AUTOSAR XML (schema 4-0-3)
standard types defined: Boolean, UInt16
package /AUTOSAR_Platform/DataConstrs
  range DC_Boolean: raw 0..1
  range DC_UInt16: raw 0..65535
package /PATAC/MSM/ComponentTypes
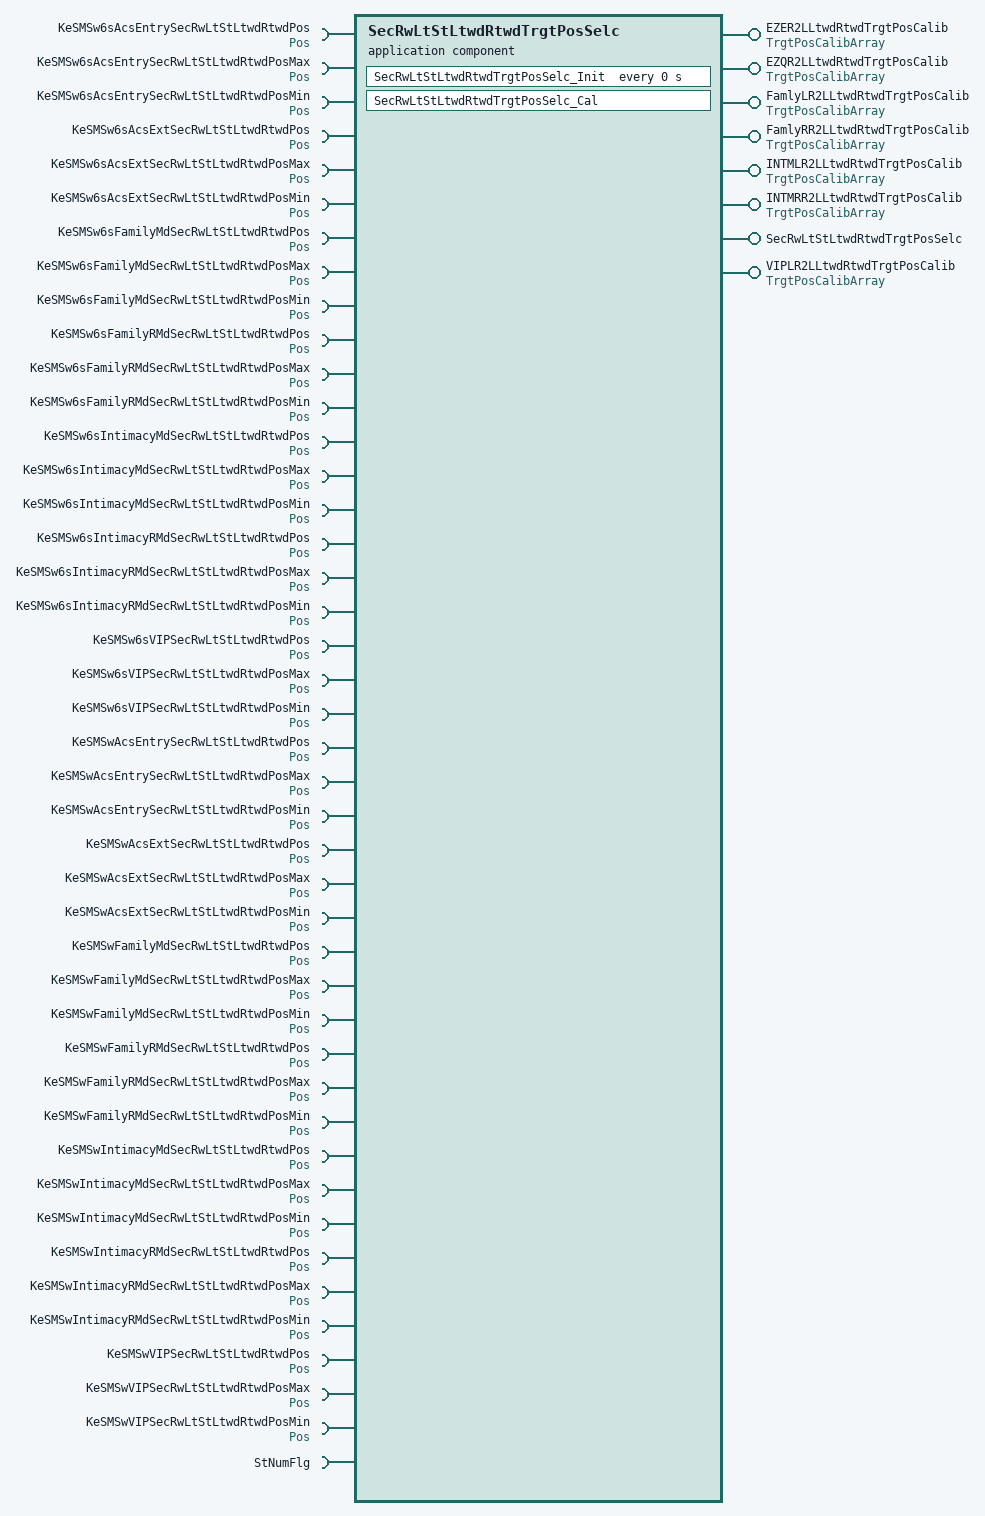
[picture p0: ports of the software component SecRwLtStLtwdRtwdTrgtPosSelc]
  application sw component type SecRwLtStLtwdRtwdTrgtPosSelc
    8 x provide port:
      EZER2LLtwdRtwdTrgtPosCalib: nonqueued-sender-com-spec{data-element=TrgtPosArray, init-value=[4095, 4095, 4095]}, provided-interface=TrgtPosCalibArray
      EZQR2LLtwdRtwdTrgtPosCalib: nonqueued-sender-com-spec{data-element=TrgtPosArray, init-value=[4095, 4095, 4095]}, provided-interface=TrgtPosCalibArray
      FamlyLR2LLtwdRtwdTrgtPosCalib: nonqueued-sender-com-spec{data-element=TrgtPosArray, init-value=[4095, 4095, 4095]}, provided-interface=TrgtPosCalibArray
      FamlyRR2LLtwdRtwdTrgtPosCalib: nonqueued-sender-com-spec{data-element=TrgtPosArray, init-value=[4095, 4095, 4095]}, provided-interface=TrgtPosCalibArray
      INTMLR2LLtwdRtwdTrgtPosCalib: nonqueued-sender-com-spec{data-element=TrgtPosArray, init-value=[4095, 4095, 4095]}, provided-interface=TrgtPosCalibArray
      INTMRR2LLtwdRtwdTrgtPosCalib: nonqueued-sender-com-spec{data-element=TrgtPosArray, init-value=[4095, 4095, 4095]}, provided-interface=TrgtPosCalibArray
      SecRwLtStLtwdRtwdTrgtPosSelc: server-com-spec{operation=Cal, queue-length=1}, provided-interface=SecRwLtStLtwdRtwdTrgtPosSelc
      VIPLR2LLtwdRtwdTrgtPosCalib: nonqueued-sender-com-spec{data-element=TrgtPosArray, init-value=[4095, 4095, 4095]}, provided-interface=TrgtPosCalibArray
    43 x require port:
      KeSMSw6sAcsEntrySecRwLtStLtwdRtwdPos: parameter-require-com-spec{init-value=0, parameter=Val}, required-interface=Pos
      KeSMSw6sAcsEntrySecRwLtStLtwdRtwdPosMax: parameter-require-com-spec{init-value=0, parameter=Val}, required-interface=Pos
      KeSMSw6sAcsEntrySecRwLtStLtwdRtwdPosMin: parameter-require-com-spec{init-value=0, parameter=Val}, required-interface=Pos
      KeSMSw6sAcsExtSecRwLtStLtwdRtwdPos: parameter-require-com-spec{init-value=0, parameter=Val}, required-interface=Pos
      KeSMSw6sAcsExtSecRwLtStLtwdRtwdPosMax: parameter-require-com-spec{init-value=0, parameter=Val}, required-interface=Pos
      KeSMSw6sAcsExtSecRwLtStLtwdRtwdPosMin: parameter-require-com-spec{init-value=0, parameter=Val}, required-interface=Pos
      KeSMSw6sFamilyMdSecRwLtStLtwdRtwdPos: parameter-require-com-spec{init-value=0, parameter=Val}, required-interface=Pos
      KeSMSw6sFamilyMdSecRwLtStLtwdRtwdPosMax: parameter-require-com-spec{init-value=0, parameter=Val}, required-interface=Pos
      KeSMSw6sFamilyMdSecRwLtStLtwdRtwdPosMin: parameter-require-com-spec{init-value=0, parameter=Val}, required-interface=Pos
      KeSMSw6sFamilyRMdSecRwLtStLtwdRtwdPos: parameter-require-com-spec{init-value=0, parameter=Val}, required-interface=Pos
      KeSMSw6sFamilyRMdSecRwLtStLtwdRtwdPosMax: parameter-require-com-spec{init-value=0, parameter=Val}, required-interface=Pos
      KeSMSw6sFamilyRMdSecRwLtStLtwdRtwdPosMin: parameter-require-com-spec{init-value=0, parameter=Val}, required-interface=Pos
      KeSMSw6sIntimacyMdSecRwLtStLtwdRtwdPos: parameter-require-com-spec{init-value=0, parameter=Val}, required-interface=Pos
      KeSMSw6sIntimacyMdSecRwLtStLtwdRtwdPosMax: parameter-require-com-spec{init-value=0, parameter=Val}, required-interface=Pos
      KeSMSw6sIntimacyMdSecRwLtStLtwdRtwdPosMin: parameter-require-com-spec{init-value=0, parameter=Val}, required-interface=Pos
      KeSMSw6sIntimacyRMdSecRwLtStLtwdRtwdPos: parameter-require-com-spec{init-value=0, parameter=Val}, required-interface=Pos
      KeSMSw6sIntimacyRMdSecRwLtStLtwdRtwdPosMax: parameter-require-com-spec{init-value=0, parameter=Val}, required-interface=Pos
      KeSMSw6sIntimacyRMdSecRwLtStLtwdRtwdPosMin: parameter-require-com-spec{init-value=0, parameter=Val}, required-interface=Pos
      KeSMSw6sVIPSecRwLtStLtwdRtwdPos: parameter-require-com-spec{init-value=4000, parameter=Val}, required-interface=Pos
      KeSMSw6sVIPSecRwLtStLtwdRtwdPosMax: parameter-require-com-spec{init-value=4000, parameter=Val}, required-interface=Pos
      KeSMSw6sVIPSecRwLtStLtwdRtwdPosMin: parameter-require-com-spec{init-value=4000, parameter=Val}, required-interface=Pos
      KeSMSwAcsEntrySecRwLtStLtwdRtwdPos: parameter-require-com-spec{init-value=0, parameter=Val}, required-interface=Pos
      KeSMSwAcsEntrySecRwLtStLtwdRtwdPosMax: parameter-require-com-spec{init-value=0, parameter=Val}, required-interface=Pos
      KeSMSwAcsEntrySecRwLtStLtwdRtwdPosMin: parameter-require-com-spec{init-value=0, parameter=Val}, required-interface=Pos
      KeSMSwAcsExtSecRwLtStLtwdRtwdPos: parameter-require-com-spec{init-value=0, parameter=Val}, required-interface=Pos
      KeSMSwAcsExtSecRwLtStLtwdRtwdPosMax: parameter-require-com-spec{init-value=0, parameter=Val}, required-interface=Pos
      KeSMSwAcsExtSecRwLtStLtwdRtwdPosMin: parameter-require-com-spec{init-value=0, parameter=Val}, required-interface=Pos
      KeSMSwFamilyMdSecRwLtStLtwdRtwdPos: parameter-require-com-spec{init-value=0, parameter=Val}, required-interface=Pos
      KeSMSwFamilyMdSecRwLtStLtwdRtwdPosMax: parameter-require-com-spec{init-value=0, parameter=Val}, required-interface=Pos
      KeSMSwFamilyMdSecRwLtStLtwdRtwdPosMin: parameter-require-com-spec{init-value=0, parameter=Val}, required-interface=Pos
      KeSMSwFamilyRMdSecRwLtStLtwdRtwdPos: parameter-require-com-spec{init-value=0, parameter=Val}, required-interface=Pos
      KeSMSwFamilyRMdSecRwLtStLtwdRtwdPosMax: parameter-require-com-spec{init-value=0, parameter=Val}, required-interface=Pos
      KeSMSwFamilyRMdSecRwLtStLtwdRtwdPosMin: parameter-require-com-spec{init-value=0, parameter=Val}, required-interface=Pos
      KeSMSwIntimacyMdSecRwLtStLtwdRtwdPos: parameter-require-com-spec{init-value=0, parameter=Val}, required-interface=Pos
      KeSMSwIntimacyMdSecRwLtStLtwdRtwdPosMax: parameter-require-com-spec{init-value=0, parameter=Val}, required-interface=Pos
      KeSMSwIntimacyMdSecRwLtStLtwdRtwdPosMin: parameter-require-com-spec{init-value=0, parameter=Val}, required-interface=Pos
      KeSMSwIntimacyRMdSecRwLtStLtwdRtwdPos: parameter-require-com-spec{init-value=0, parameter=Val}, required-interface=Pos
      KeSMSwIntimacyRMdSecRwLtStLtwdRtwdPosMax: parameter-require-com-spec{init-value=0, parameter=Val}, required-interface=Pos
      KeSMSwIntimacyRMdSecRwLtStLtwdRtwdPosMin: parameter-require-com-spec{init-value=0, parameter=Val}, required-interface=Pos
      KeSMSwVIPSecRwLtStLtwdRtwdPos: parameter-require-com-spec{init-value=4000, parameter=Val}, required-interface=Pos
      KeSMSwVIPSecRwLtStLtwdRtwdPosMax: parameter-require-com-spec{init-value=4000, parameter=Val}, required-interface=Pos
      KeSMSwVIPSecRwLtStLtwdRtwdPosMin: parameter-require-com-spec{init-value=4000, parameter=Val}, required-interface=Pos
      StNumFlg: required-interface=StNumFlg
        required-com-specs:
          data-element=Is4s, filter=data-filter-type=ALWAYS, init-value=0
          data-element=Is6s, filter=data-filter-type=ALWAYS, init-value=0
          data-element=Is6s7s, filter=data-filter-type=ALWAYS, init-value=0
          data-element=Is7s, filter=data-filter-type=ALWAYS, init-value=0
    behavior SecRwLtStLtwdRtwdTrgtPosSelc_InternalBehavior
      operation invoked event OIT_SecRwLtStLtwdRtwdTrgtPosSelc_Cal_SecRwLtStLtwdRtwdTrgtPosSelc_Cal: start-on-event=SecRwLtStLtwdRtwdTrgtPosSelc_Cal, operation=SecRwLtStLtwdRtwdTrgtPosSelc.Cal
      timing event SecRwLtStLtwdRtwdTrgtPosSelc_InitEvent: start-on-event=SecRwLtStLtwdRtwdTrgtPosSelc_Init, period=0
      runnable SecRwLtStLtwdRtwdTrgtPosSelc_Cal
        data-receive-point-by-arguments:
          4 x access:
            REC_StNumFlg_Is4s: accessed-variable=StNumFlg.Is4s
            REC_StNumFlg_Is6s: accessed-variable=StNumFlg.Is6s
            REC_StNumFlg_Is6s7s: accessed-variable=StNumFlg.Is6s7s
            REC_StNumFlg_Is7s: accessed-variable=StNumFlg.Is7s
        data-send-points:
          7 x access:
            SEND_EZER2LLtwdRtwdTrgtPosCalib_TrgtPosArray: accessed-variable=EZER2LLtwdRtwdTrgtPosCalib.TrgtPosArray
            SEND_EZQR2LLtwdRtwdTrgtPosCalib_TrgtPosArray: accessed-variable=EZQR2LLtwdRtwdTrgtPosCalib.TrgtPosArray
            SEND_FamlyLR2LLtwdRtwdTrgtPosCalib_TrgtPosArray: accessed-variable=FamlyLR2LLtwdRtwdTrgtPosCalib.TrgtPosArray
            SEND_FamlyRR2LLtwdRtwdTrgtPosCalib_TrgtPosArray: accessed-variable=FamlyRR2LLtwdRtwdTrgtPosCalib.TrgtPosArray
            SEND_INTMLR2LLtwdRtwdTrgtPosCalib_TrgtPosArray: accessed-variable=INTMLR2LLtwdRtwdTrgtPosCalib.TrgtPosArray
            SEND_INTMRR2LLtwdRtwdTrgtPosCalib_TrgtPosArray: accessed-variable=INTMRR2LLtwdRtwdTrgtPosCalib.TrgtPosArray
            SEND_VIPLR2LLtwdRtwdTrgtPosCalib_TrgtPosArray: accessed-variable=VIPLR2LLtwdRtwdTrgtPosCalib.TrgtPosArray
        42 x parameter access:
          PA_KeSMSw6sAcsEntrySecRwLtStLtwdRtwdPos_Val: accessed-parameter=KeSMSw6sAcsEntrySecRwLtStLtwdRtwdPos.Val
          PA_KeSMSw6sAcsEntrySecRwLtStLtwdRtwdPosMax_Val: accessed-parameter=KeSMSw6sAcsEntrySecRwLtStLtwdRtwdPosMax.Val
          PA_KeSMSw6sAcsEntrySecRwLtStLtwdRtwdPosMin_Val: accessed-parameter=KeSMSw6sAcsEntrySecRwLtStLtwdRtwdPosMin.Val
          PA_KeSMSw6sAcsExtSecRwLtStLtwdRtwdPos_Val: accessed-parameter=KeSMSw6sAcsExtSecRwLtStLtwdRtwdPos.Val
          PA_KeSMSw6sAcsExtSecRwLtStLtwdRtwdPosMax_Val: accessed-parameter=KeSMSw6sAcsExtSecRwLtStLtwdRtwdPosMax.Val
          PA_KeSMSw6sAcsExtSecRwLtStLtwdRtwdPosMin_Val: accessed-parameter=KeSMSw6sAcsExtSecRwLtStLtwdRtwdPosMin.Val
          PA_KeSMSw6sFamilyMdSecRwLtStLtwdRtwdPos_Val: accessed-parameter=KeSMSw6sFamilyMdSecRwLtStLtwdRtwdPos.Val
          PA_KeSMSw6sFamilyMdSecRwLtStLtwdRtwdPosMax_Val: accessed-parameter=KeSMSw6sFamilyMdSecRwLtStLtwdRtwdPosMax.Val
          PA_KeSMSw6sFamilyMdSecRwLtStLtwdRtwdPosMin_Val: accessed-parameter=KeSMSw6sFamilyMdSecRwLtStLtwdRtwdPosMin.Val
          PA_KeSMSw6sFamilyRMdSecRwLtStLtwdRtwdPos_Val: accessed-parameter=KeSMSw6sFamilyRMdSecRwLtStLtwdRtwdPos.Val
          PA_KeSMSw6sFamilyRMdSecRwLtStLtwdRtwdPosMax_Val: accessed-parameter=KeSMSw6sFamilyRMdSecRwLtStLtwdRtwdPosMax.Val
          PA_KeSMSw6sFamilyRMdSecRwLtStLtwdRtwdPosMin_Val: accessed-parameter=KeSMSw6sFamilyRMdSecRwLtStLtwdRtwdPosMin.Val
          PA_KeSMSw6sIntimacyMdSecRwLtStLtwdRtwdPos_Val: accessed-parameter=KeSMSw6sIntimacyMdSecRwLtStLtwdRtwdPos.Val
          PA_KeSMSw6sIntimacyMdSecRwLtStLtwdRtwdPosMax_Val: accessed-parameter=KeSMSw6sIntimacyMdSecRwLtStLtwdRtwdPosMax.Val
          PA_KeSMSw6sIntimacyMdSecRwLtStLtwdRtwdPosMin_Val: accessed-parameter=KeSMSw6sIntimacyMdSecRwLtStLtwdRtwdPosMin.Val
          PA_KeSMSw6sIntimacyRMdSecRwLtStLtwdRtwdPos_Val: accessed-parameter=KeSMSw6sIntimacyRMdSecRwLtStLtwdRtwdPos.Val
          PA_KeSMSw6sIntimacyRMdSecRwLtStLtwdRtwdPosMax_Val: accessed-parameter=KeSMSw6sIntimacyRMdSecRwLtStLtwdRtwdPosMax.Val
          PA_KeSMSw6sIntimacyRMdSecRwLtStLtwdRtwdPosMin_Val: accessed-parameter=KeSMSw6sIntimacyRMdSecRwLtStLtwdRtwdPosMin.Val
          PA_KeSMSw6sVIPSecRwLtStLtwdRtwdPos_Val: accessed-parameter=KeSMSw6sVIPSecRwLtStLtwdRtwdPos.Val
          PA_KeSMSw6sVIPSecRwLtStLtwdRtwdPosMax_Val: accessed-parameter=KeSMSw6sVIPSecRwLtStLtwdRtwdPosMax.Val
          PA_KeSMSw6sVIPSecRwLtStLtwdRtwdPosMin_Val: accessed-parameter=KeSMSw6sVIPSecRwLtStLtwdRtwdPosMin.Val
          PA_KeSMSwAcsEntrySecRwLtStLtwdRtwdPos_Val: accessed-parameter=KeSMSwAcsEntrySecRwLtStLtwdRtwdPos.Val
          PA_KeSMSwAcsEntrySecRwLtStLtwdRtwdPosMax_Val: accessed-parameter=KeSMSwAcsEntrySecRwLtStLtwdRtwdPosMax.Val
          PA_KeSMSwAcsEntrySecRwLtStLtwdRtwdPosMin_Val: accessed-parameter=KeSMSwAcsEntrySecRwLtStLtwdRtwdPosMin.Val
          PA_KeSMSwAcsExtSecRwLtStLtwdRtwdPos_Val: accessed-parameter=KeSMSwAcsExtSecRwLtStLtwdRtwdPos.Val
          PA_KeSMSwAcsExtSecRwLtStLtwdRtwdPosMax_Val: accessed-parameter=KeSMSwAcsExtSecRwLtStLtwdRtwdPosMax.Val
          PA_KeSMSwAcsExtSecRwLtStLtwdRtwdPosMin_Val: accessed-parameter=KeSMSwAcsExtSecRwLtStLtwdRtwdPosMin.Val
          PA_KeSMSwFamilyMdSecRwLtStLtwdRtwdPos_Val: accessed-parameter=KeSMSwFamilyMdSecRwLtStLtwdRtwdPos.Val
          PA_KeSMSwFamilyMdSecRwLtStLtwdRtwdPosMax_Val: accessed-parameter=KeSMSwFamilyMdSecRwLtStLtwdRtwdPosMax.Val
          PA_KeSMSwFamilyMdSecRwLtStLtwdRtwdPosMin_Val: accessed-parameter=KeSMSwFamilyMdSecRwLtStLtwdRtwdPosMin.Val
          PA_KeSMSwFamilyRMdSecRwLtStLtwdRtwdPos_Val: accessed-parameter=KeSMSwFamilyRMdSecRwLtStLtwdRtwdPos.Val
          PA_KeSMSwFamilyRMdSecRwLtStLtwdRtwdPosMax_Val: accessed-parameter=KeSMSwFamilyRMdSecRwLtStLtwdRtwdPosMax.Val
          PA_KeSMSwFamilyRMdSecRwLtStLtwdRtwdPosMin_Val: accessed-parameter=KeSMSwFamilyRMdSecRwLtStLtwdRtwdPosMin.Val
          PA_KeSMSwIntimacyMdSecRwLtStLtwdRtwdPos_Val: accessed-parameter=KeSMSwIntimacyMdSecRwLtStLtwdRtwdPos.Val
          PA_KeSMSwIntimacyMdSecRwLtStLtwdRtwdPosMax_Val: accessed-parameter=KeSMSwIntimacyMdSecRwLtStLtwdRtwdPosMax.Val
          PA_KeSMSwIntimacyMdSecRwLtStLtwdRtwdPosMin_Val: accessed-parameter=KeSMSwIntimacyMdSecRwLtStLtwdRtwdPosMin.Val
          PA_KeSMSwIntimacyRMdSecRwLtStLtwdRtwdPos_Val: accessed-parameter=KeSMSwIntimacyRMdSecRwLtStLtwdRtwdPos.Val
          PA_KeSMSwIntimacyRMdSecRwLtStLtwdRtwdPosMax_Val: accessed-parameter=KeSMSwIntimacyRMdSecRwLtStLtwdRtwdPosMax.Val
          PA_KeSMSwIntimacyRMdSecRwLtStLtwdRtwdPosMin_Val: accessed-parameter=KeSMSwIntimacyRMdSecRwLtStLtwdRtwdPosMin.Val
          PA_KeSMSwVIPSecRwLtStLtwdRtwdPos_Val: accessed-parameter=KeSMSwVIPSecRwLtStLtwdRtwdPos.Val
          PA_KeSMSwVIPSecRwLtStLtwdRtwdPosMax_Val: accessed-parameter=KeSMSwVIPSecRwLtStLtwdRtwdPosMax.Val
          PA_KeSMSwVIPSecRwLtStLtwdRtwdPosMin_Val: accessed-parameter=KeSMSwVIPSecRwLtStLtwdRtwdPosMin.Val
      runnable SecRwLtStLtwdRtwdTrgtPosSelc_Init
        42 x parameter access:
          PA_KeSMSw6sAcsEntrySecRwLtStLtwdRtwdPos_Val: accessed-parameter=KeSMSw6sAcsEntrySecRwLtStLtwdRtwdPos.Val
          PA_KeSMSw6sAcsEntrySecRwLtStLtwdRtwdPosMax_Val: accessed-parameter=KeSMSw6sAcsEntrySecRwLtStLtwdRtwdPosMax.Val
          PA_KeSMSw6sAcsEntrySecRwLtStLtwdRtwdPosMin_Val: accessed-parameter=KeSMSw6sAcsEntrySecRwLtStLtwdRtwdPosMin.Val
          PA_KeSMSw6sAcsExtSecRwLtStLtwdRtwdPos_Val: accessed-parameter=KeSMSw6sAcsExtSecRwLtStLtwdRtwdPos.Val
          PA_KeSMSw6sAcsExtSecRwLtStLtwdRtwdPosMax_Val: accessed-parameter=KeSMSw6sAcsExtSecRwLtStLtwdRtwdPosMax.Val
          PA_KeSMSw6sAcsExtSecRwLtStLtwdRtwdPosMin_Val: accessed-parameter=KeSMSw6sAcsExtSecRwLtStLtwdRtwdPosMin.Val
          PA_KeSMSw6sFamilyMdSecRwLtStLtwdRtwdPos_Val: accessed-parameter=KeSMSw6sFamilyMdSecRwLtStLtwdRtwdPos.Val
          PA_KeSMSw6sFamilyMdSecRwLtStLtwdRtwdPosMax_Val: accessed-parameter=KeSMSw6sFamilyMdSecRwLtStLtwdRtwdPosMax.Val
          PA_KeSMSw6sFamilyMdSecRwLtStLtwdRtwdPosMin_Val: accessed-parameter=KeSMSw6sFamilyMdSecRwLtStLtwdRtwdPosMin.Val
          PA_KeSMSw6sFamilyRMdSecRwLtStLtwdRtwdPos_Val: accessed-parameter=KeSMSw6sFamilyRMdSecRwLtStLtwdRtwdPos.Val
          PA_KeSMSw6sFamilyRMdSecRwLtStLtwdRtwdPosMax_Val: accessed-parameter=KeSMSw6sFamilyRMdSecRwLtStLtwdRtwdPosMax.Val
          PA_KeSMSw6sFamilyRMdSecRwLtStLtwdRtwdPosMin_Val: accessed-parameter=KeSMSw6sFamilyRMdSecRwLtStLtwdRtwdPosMin.Val
          PA_KeSMSw6sIntimacyMdSecRwLtStLtwdRtwdPos_Val: accessed-parameter=KeSMSw6sIntimacyMdSecRwLtStLtwdRtwdPos.Val
          PA_KeSMSw6sIntimacyMdSecRwLtStLtwdRtwdPosMax_Val: accessed-parameter=KeSMSw6sIntimacyMdSecRwLtStLtwdRtwdPosMax.Val
          PA_KeSMSw6sIntimacyMdSecRwLtStLtwdRtwdPosMin_Val: accessed-parameter=KeSMSw6sIntimacyMdSecRwLtStLtwdRtwdPosMin.Val
          PA_KeSMSw6sIntimacyRMdSecRwLtStLtwdRtwdPos_Val: accessed-parameter=KeSMSw6sIntimacyRMdSecRwLtStLtwdRtwdPos.Val
          PA_KeSMSw6sIntimacyRMdSecRwLtStLtwdRtwdPosMax_Val: accessed-parameter=KeSMSw6sIntimacyRMdSecRwLtStLtwdRtwdPosMax.Val
          PA_KeSMSw6sIntimacyRMdSecRwLtStLtwdRtwdPosMin_Val: accessed-parameter=KeSMSw6sIntimacyRMdSecRwLtStLtwdRtwdPosMin.Val
          PA_KeSMSw6sVIPSecRwLtStLtwdRtwdPos_Val: accessed-parameter=KeSMSw6sVIPSecRwLtStLtwdRtwdPos.Val
          PA_KeSMSw6sVIPSecRwLtStLtwdRtwdPosMax_Val: accessed-parameter=KeSMSw6sVIPSecRwLtStLtwdRtwdPosMax.Val
          PA_KeSMSw6sVIPSecRwLtStLtwdRtwdPosMin_Val: accessed-parameter=KeSMSw6sVIPSecRwLtStLtwdRtwdPosMin.Val
          PA_KeSMSwAcsEntrySecRwLtStLtwdRtwdPos_Val: accessed-parameter=KeSMSwAcsEntrySecRwLtStLtwdRtwdPos.Val
          PA_KeSMSwAcsEntrySecRwLtStLtwdRtwdPosMax_Val: accessed-parameter=KeSMSwAcsEntrySecRwLtStLtwdRtwdPosMax.Val
          PA_KeSMSwAcsEntrySecRwLtStLtwdRtwdPosMin_Val: accessed-parameter=KeSMSwAcsEntrySecRwLtStLtwdRtwdPosMin.Val
          PA_KeSMSwAcsExtSecRwLtStLtwdRtwdPos_Val: accessed-parameter=KeSMSwAcsExtSecRwLtStLtwdRtwdPos.Val
          PA_KeSMSwAcsExtSecRwLtStLtwdRtwdPosMax_Val: accessed-parameter=KeSMSwAcsExtSecRwLtStLtwdRtwdPosMax.Val
          PA_KeSMSwAcsExtSecRwLtStLtwdRtwdPosMin_Val: accessed-parameter=KeSMSwAcsExtSecRwLtStLtwdRtwdPosMin.Val
          PA_KeSMSwFamilyMdSecRwLtStLtwdRtwdPos_Val: accessed-parameter=KeSMSwFamilyMdSecRwLtStLtwdRtwdPos.Val
          PA_KeSMSwFamilyMdSecRwLtStLtwdRtwdPosMax_Val: accessed-parameter=KeSMSwFamilyMdSecRwLtStLtwdRtwdPosMax.Val
          PA_KeSMSwFamilyMdSecRwLtStLtwdRtwdPosMin_Val: accessed-parameter=KeSMSwFamilyMdSecRwLtStLtwdRtwdPosMin.Val
          PA_KeSMSwFamilyRMdSecRwLtStLtwdRtwdPos_Val: accessed-parameter=KeSMSwFamilyRMdSecRwLtStLtwdRtwdPos.Val
          PA_KeSMSwFamilyRMdSecRwLtStLtwdRtwdPosMax_Val: accessed-parameter=KeSMSwFamilyRMdSecRwLtStLtwdRtwdPosMax.Val
          PA_KeSMSwFamilyRMdSecRwLtStLtwdRtwdPosMin_Val: accessed-parameter=KeSMSwFamilyRMdSecRwLtStLtwdRtwdPosMin.Val
          PA_KeSMSwIntimacyMdSecRwLtStLtwdRtwdPos_Val: accessed-parameter=KeSMSwIntimacyMdSecRwLtStLtwdRtwdPos.Val
          PA_KeSMSwIntimacyMdSecRwLtStLtwdRtwdPosMax_Val: accessed-parameter=KeSMSwIntimacyMdSecRwLtStLtwdRtwdPosMax.Val
          PA_KeSMSwIntimacyMdSecRwLtStLtwdRtwdPosMin_Val: accessed-parameter=KeSMSwIntimacyMdSecRwLtStLtwdRtwdPosMin.Val
          PA_KeSMSwIntimacyRMdSecRwLtStLtwdRtwdPos_Val: accessed-parameter=KeSMSwIntimacyRMdSecRwLtStLtwdRtwdPos.Val
          PA_KeSMSwIntimacyRMdSecRwLtStLtwdRtwdPosMax_Val: accessed-parameter=KeSMSwIntimacyRMdSecRwLtStLtwdRtwdPosMax.Val
          PA_KeSMSwIntimacyRMdSecRwLtStLtwdRtwdPosMin_Val: accessed-parameter=KeSMSwIntimacyRMdSecRwLtStLtwdRtwdPosMin.Val
          PA_KeSMSwVIPSecRwLtStLtwdRtwdPos_Val: accessed-parameter=KeSMSwVIPSecRwLtStLtwdRtwdPos.Val
          PA_KeSMSwVIPSecRwLtStLtwdRtwdPosMax_Val: accessed-parameter=KeSMSwVIPSecRwLtStLtwdRtwdPosMax.Val
          PA_KeSMSwVIPSecRwLtStLtwdRtwdPosMin_Val: accessed-parameter=KeSMSwVIPSecRwLtStLtwdRtwdPosMin.Val
  swc implementation SecRwLtStLtwdRtwdTrgtPosSelc_Implementation: behavior=SecRwLtStLtwdRtwdTrgtPosSelc_InternalBehavior
    code-descriptors:
      code Default: artifact-descriptors=autosar-engineering-object={short-label=Default, category=SWSRC}
package /PATAC/MSM/ModeAdjust/CalPortInterface
  parameter interface Pos
    parameter data prototype Val: sw-calibration-access=READ-WRITE, type=UInt16
package /PATAC/MSM/ModeAdjust/DataType
  impl type TrgtPosCalibArray: category=ARRAY, sw-calibration-access=READ-ONLY, type-emitter=RTE  # 0:pos 1:max 2:min
    element Element: array-size=3, array-size-semantics=FIXED-SIZE, implementation-data-type=UInt16, invalid-value=0
package /PATAC/MSM/ModeAdjust/PortInterface
  client server interface SecRwLtStLtwdRtwdTrgtPosSelc
    operation Cal
  sender receiver interface StNumFlg
    4 x data, all with type=Boolean:
      Is4s
      Is6s
      Is6s7s
      Is7s
    invalidation-policys:
      data-element=Is7s, handle-invalid=DONT-INVALIDATE
      data-element=Is6s, handle-invalid=DONT-INVALIDATE
      data-element=Is4s, handle-invalid=DONT-INVALIDATE
      data-element=Is6s7s, handle-invalid=DONT-INVALIDATE
  sender receiver interface TrgtPosCalibArray: invalidation-policy{data-element=TrgtPosArray, handle-invalid=DONT-INVALIDATE}
    data TrgtPosArray: type=TrgtPosCalibArray  # 0:Pos 1:Max 2:Min
